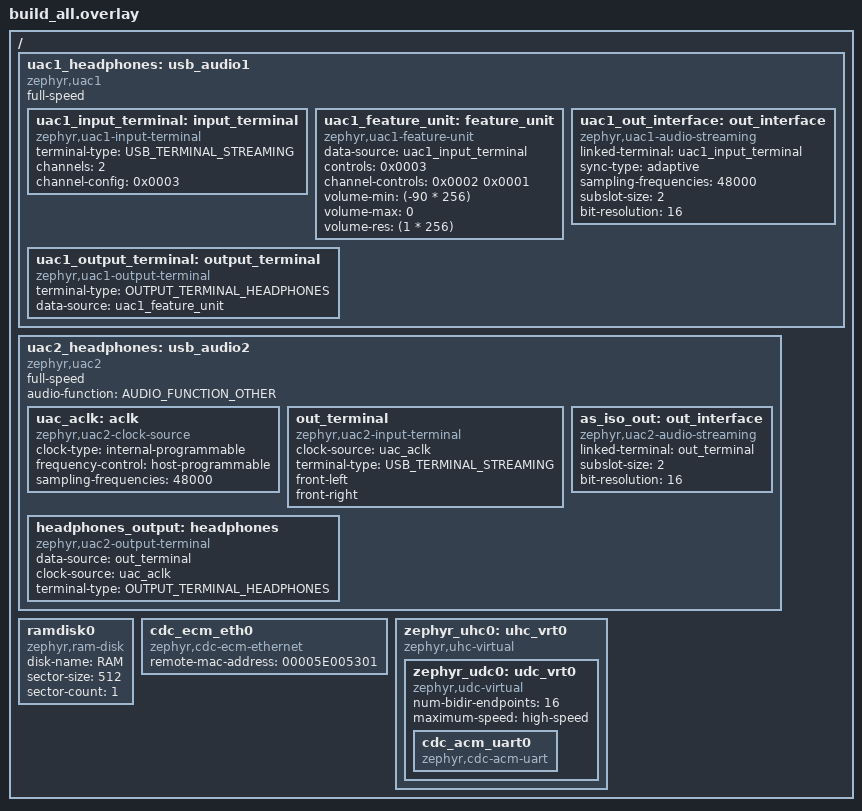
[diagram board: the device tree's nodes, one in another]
/*
 * Copyright (c) 2024 Nordic Semiconductor ASA
 *
 * SPDX-License-Identifier: Apache-2.0
 */

/delete-node/ &zephyr_udc0;

#include <zephyr/dt-bindings/usb/audio.h>

/ {
	uac1_headphones: usb_audio1 {
		compatible = "zephyr,uac1";
		status = "okay";
		full-speed;

		uac1_input_terminal: input_terminal {
			compatible = "zephyr,uac1-input-terminal";
			terminal-type = <USB_TERMINAL_STREAMING>;
			channels = <2>;
			channel-config = <0x0003>;
		};

		uac1_feature_unit: feature_unit {
			compatible = "zephyr,uac1-feature-unit";
			data-source = <&uac1_input_terminal>;
			controls = <0x0003>;
			channel-controls = <0x0002 0x0001>;
			volume-min = <(-90 * 256)>;
			volume-max = <0>;
			volume-res = <(1 * 256)>;
		};

		uac1_output_terminal: output_terminal {
			compatible = "zephyr,uac1-output-terminal";
			terminal-type = <OUTPUT_TERMINAL_HEADPHONES>;
			data-source = <&uac1_feature_unit>;
		};

		uac1_out_interface: out_interface {
			compatible = "zephyr,uac1-audio-streaming";
			linked-terminal = <&uac1_input_terminal>;
			sync-type = "adaptive";
			sampling-frequencies = <48000>;
			subslot-size = <2>;
			bit-resolution = <16>;
		};
	};

	uac2_headphones: usb_audio2 {
		compatible = "zephyr,uac2";
		status = "okay";
		full-speed;
		audio-function = <AUDIO_FUNCTION_OTHER>;

		uac_aclk: aclk {
			compatible = "zephyr,uac2-clock-source";
			clock-type = "internal-programmable";
			frequency-control = "host-programmable";
			sampling-frequencies = <48000>;
		};

		out_terminal: out_terminal {
			compatible = "zephyr,uac2-input-terminal";
			clock-source = <&uac_aclk>;
			terminal-type = <USB_TERMINAL_STREAMING>;
			front-left;
			front-right;
		};

		headphones_output: headphones {
			compatible = "zephyr,uac2-output-terminal";
			data-source = <&out_terminal>;
			clock-source = <&uac_aclk>;
			terminal-type = <OUTPUT_TERMINAL_HEADPHONES>;
		};

		as_iso_out: out_interface {
			compatible = "zephyr,uac2-audio-streaming";
			linked-terminal = <&out_terminal>;
			subslot-size = <2>;
			bit-resolution = <16>;
		};
	};

	ramdisk0 {
		compatible = "zephyr,ram-disk";
		disk-name = "RAM";
		sector-size = <512>;
		sector-count = <1>;
	};

	cdc_ecm_eth0: cdc_ecm_eth0 {
		compatible = "zephyr,cdc-ecm-ethernet";
		remote-mac-address = "00005E005301";
	};

	zephyr_uhc0: uhc_vrt0 {
		compatible = "zephyr,uhc-virtual";

		zephyr_udc0: udc_vrt0 {
			compatible = "zephyr,udc-virtual";
			num-bidir-endpoints = <16>;
			maximum-speed = "high-speed";
		};
	};
};

&zephyr_udc0 {
	cdc_acm_uart0 {
		compatible = "zephyr,cdc-acm-uart";
	};
};
